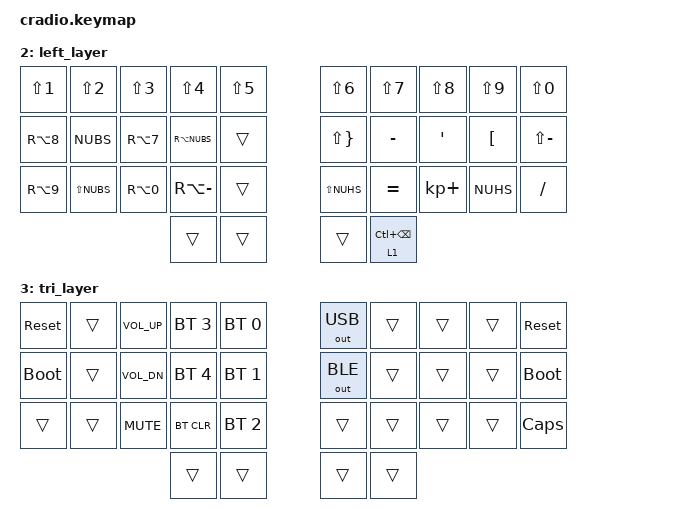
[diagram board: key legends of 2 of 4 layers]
// Copyright (c) 2022 The ZMK Contributors
// SPDX-License-Identifier: MIT

#include <behaviors.dtsi>
#include <dt-bindings/zmk/keys.h>
#include <dt-bindings/zmk/bt.h>

// Home row mods macro
#define HRML(k1,k2,k3) &ht LGUI k1  &ht LALT k2  &ht LCTRL k3
#define HRMR(k1,k2,k3) &ht RCTRL k1  &ht RALT k2  &ht RGUI k3

// Weitere macros
#define XCV(k1,k2,k3) &ht RC(X) k1  &ht RC(C) k2  &ht RC(V) k3
#define CT(k1,k2,k3,k4,k5) &ht RC(N1) k1    &ht RC(N2) k2 &ht RC(N3) k3   &ht RC(N4) k4   &ht RC(N5) k5
#define UDO(k1) &ht RC(Y) k1

&mt {
  //  flavor = "tap-preferred";
   // tapping_term_ms = <200>;
};

/ {
    combos {
        compatible = "zmk,combos";
        combo_esc {
            timeout-ms = <50>;
            key-positions = <0 1>;
            bindings = <&kp ESC>;
        };
        combo_tab {
            timeout-ms = <50>;
            key-positions = <10 11>;
            bindings = <&kp TAB>;
        };
        combo_capslock {
            timeout-ms = <50>;
            key-positions = <20 21>;
            bindings = <&kp CAPS>;
        };   
        combo_del {
            timeout-ms = <50>;
            key-positions = <26 27>;
            bindings = <&kp DEL>;
        };
    };
};

/ {
    behaviors {
        ht: hold_tap {
            label = "hold_tap";
            compatible = "zmk,behavior-hold-tap";
            #binding-cells = <2>;
            flavor = "tap-preferred";
            tapping-term-ms = <220>;
            quick-tap-ms = <150>;
            global-quick-tap;
            bindings = <&kp>, <&kp>;
        };
    };
    conditional_layers {
        compatible = "zmk,conditional-layers";
        tri_layer {
            if-layers = <1 2>;
            then-layer = <3>;
        };
    };

    keymap {
        compatible = "zmk,keymap";
        default_layer {
            bindings = <
        //╭──────────┬──────────┬──────────┬──────────┬──────────╮   ╭──────────┬──────────┬──────────┬──────────┬──────────╮
        //│  Q       │  W       │  E       │  R       │  T       │   │  Y       │  U       │  I       │  O       │  P       │
            &kp Q      &kp W      &kp E      &kp R      &kp T          UDO(Y)       &kp U      &kp I      &kp O      &kp P
        //├──────────┼──────────┼──────────┼──────────┼──────────┤   ├──────────┼──────────┼──────────┼──────────┼──────────┤
        //│  A       │  S       │  D       │  F       │  G       │   │  H       │  J       │  K       │  L       │ ' "      │
            &kp A      HRML( S,         D,         F)     &kp G          &kp H      HRMR(J,        K,         L)    &kp SEMI
        //├──────────┼──────────┼──────────┼──────────┼──────────┤   ├──────────┼──────────┼──────────┼──────────┼──────────┤
        //│  Z       │  X       │  C       │  V       │  B       │   │  N       │  M       │ , <      │ . >      │ / ?      │
            &mt LSHFT Z   XCV( X,    C,       V)      &kp B          &kp N      &kp M      &kp COMMA  &kp DOT    &mt RSHFT FSLH
        //╰──────────┴──────────┴──────────┼──────────┼──────────┤   ├──────────┼──────────┼──────────┴──────────┴──────────╯
                                            &mo 2   &mt LSHFT ENTER     &kp SPACE  &lt 1 BSPC
        //                                 ╰──────────┴──────────╯   ╰──────────┴──────────╯
            >;
        };


        right_layer {
            bindings = <
        //╭──────────┬──────────┬──────────┬──────────┬──────────╮   ╭──────────┬──────────┬──────────┬──────────┬──────────╮
        //│ 1        │  2       │     3    │  4       │    5     │   │   6      │  7       │    8     │ 9        │     0    │
            CT( N1,       N2,       N3,       N4,         N5)        &kp N6      &kp N7    &kp N8     &kp N9     &kp N0
        //├──────────┼──────────┼──────────┼──────────┼──────────┤   ├──────────┼──────────┼──────────┼──────────┼──────────┤
        //│ DELETE   │  4       │  5       │  6       │          │   │ LEFT     │ DOWN     │ UP       │ RIGHT    │  ;       │
            &kp F11    &kp F12    &kp PG_UP  &kp PG_DN  &kp HOME       &kp LARW   &kp DARW   &kp UARW   &kp RARW   &kp END
        //├──────────┼──────────┼──────────┼──────────┼──────────┤   ├──────────┼──────────┼──────────┼──────────┼──────────┤
        //│ CAPS     │  7       │  8       │  9       │  0       │   │          │          │          │          │          │
            &kp F1     &kp F2      &kp F3    &kp F4     &kp F5         &kp F6      &kp F7    &kp F8     &kp F9     &kp F10
        //╰──────────┴──────────┴──────────┼──────────┼──────────┤   ├──────────┼──────────┼──────────┴──────────┴──────────╯
                                             &trans     &kp ESC        &trans     &trans
        //                                 ╰──────────┴──────────╯   ╰──────────┴──────────╯
            >;
        };

  
        left_layer {
            bindings = <
        //╭──────────┬──────────┬──────────┬──────────┬──────────╮   ╭──────────┬──────────┬──────────┬──────────┬──────────╮
        //│          │  [       │  {       │  }       │          │   │  ^       │  (       │  )       │  ]       │  ~       │
            &kp LS(N1) &kp LS(N2)    &kp LS(N3)  &kp LS(N4) &kp LS(N5)      &kp LS(N6)  &kp LS(N7)  &kp LS(N8)  &kp LS(N9)  &kp LS(N0)
        //├──────────┼──────────┼──────────┼──────────┼──────────┤   ├──────────┼──────────┼──────────┼──────────┼──────────┤
        //│  !       │  @       │  #       │  $       │  %       │   │  *       │  -       │  =       │  \       │  `       │
            &kp RA(N8)  &kp NUBS   &kp RA(N7)   &kp RA(NUBS) &trans      &kp LS(RBRC) &kp MINUS  &kp SQT  &kp LBKT   &kp LS(MINUS)
        //├──────────┼──────────┼──────────┼──────────┼──────────┤   ├──────────┼──────────┼──────────┼──────────┼──────────┤
        //│          │          │          │          │          │   │  &       │  _       │  +       │  │       │          │
            &kp RA(N9)  &kp LS(NUBS) &kp RA(N0) &kp RA(MINUS) &trans     &kp LS(NUHS)    &kp EQUAL  &kp KP_PLUS  &kp NUHS  &kp SLASH

        //╰──────────┴──────────┴──────────┼──────────┼──────────┤   ├──────────┼──────────┼──────────┴──────────┴──────────╯
                                             &trans     &trans         &trans     &lt 1 LC(BSPC)
        //                                 ╰──────────┴──────────╯   ╰──────────┴──────────╯
            >;
        };

        tri_layer {
            bindings = <
        //╭──────────┬──────────┬──────────┬──────────┬──────────╮   ╭──────────┬──────────┬──────────┬──────────┬──────────╮
        //│ RESET    │          │          │          │PROFILE 0 │   │          │          │          │          │  RESET   │
           &sys_reset  &trans     &kp C_VOL_UP  &bt BT_SEL 3    &bt BT_SEL 0    &out OUT_USB   &trans     &trans     &trans    &sys_reset
        //├──────────┼──────────┼──────────┼──────────┼──────────┤   ├──────────┼──────────┼──────────┼──────────┼──────────┤
        //│BOOTLOADER│          │          │          │PROFILE 1 │   │          │          │          │          │BOOTLOADER│
          &bootloader  &trans     &kp C_VOL_DN    &bt BT_SEL 4  &bt BT_SEL 1   &out OUT_BLE   &trans      &trans     &trans    &bootloader
        //├──────────┼──────────┼──────────┼──────────┼──────────┤   ├──────────┼──────────┼──────────┼──────────┼──────────┤
        //│          │          │          │ CLEAR BT │PROFILE 2 │   │          │          │          │          │          │
            &trans     &trans     &kp C_MUTE    &bt BT_CLR &bt BT_SEL 2    &trans   &trans   &trans        &trans     &kp CAPS
        //╰──────────┴──────────┴──────────┼──────────┼──────────┤   ├──────────┼──────────┼──────────┴──────────┴──────────╯
                                             &trans     &trans         &trans     &trans
        //                                 ╰──────────┴──────────╯   ╰──────────┴──────────╯
            >;
        };
    };
};
